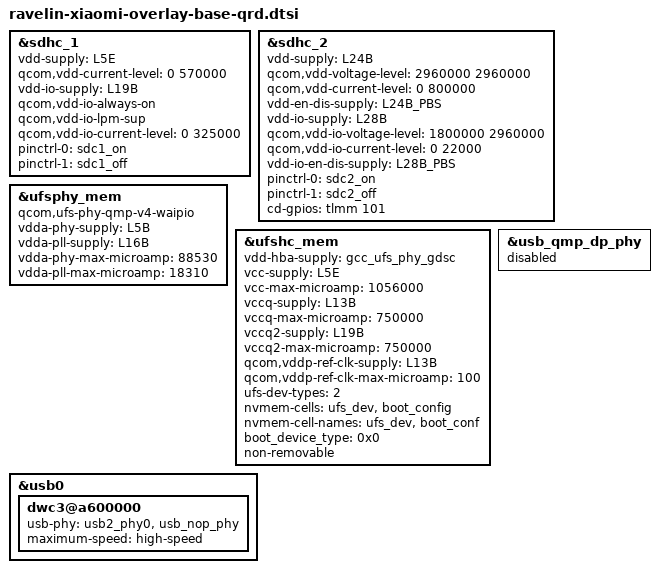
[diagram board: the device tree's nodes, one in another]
// SPDX-License-Identifier: BSD-3-Clause
/*
 * Xiaomi Ravelin board base, ravelin-qrd.dtsi with PM7250B instead of PMI632.
 */

#include "ravelin-pmic-overlay.dtsi"
#include "ravelin-pm7250b.dtsi"
#include "ravelin-thermal-overlay.dtsi"

&sdhc_1 {
	status = "ok";
	vdd-supply = <&L5E>;
	qcom,vdd-current-level = <0 570000>;

	vdd-io-supply = <&L19B>;
	qcom,vdd-io-always-on;
	qcom,vdd-io-lpm-sup;
	qcom,vdd-io-current-level = <0 325000>;

	pinctrl-names = "default", "sleep";
	pinctrl-0 = <&sdc1_on>;
	pinctrl-1 = <&sdc1_off>;
};

&sdhc_2 {
	status = "ok";
	vdd-supply = <&L24B>;
	qcom,vdd-voltage-level = <2960000 2960000>;
	qcom,vdd-current-level = <0 800000>;
	vdd-en-dis-supply = <&L24B_PBS>;

	vdd-io-supply = <&L28B>;
	qcom,vdd-io-voltage-level = <1800000 2960000>;
	qcom,vdd-io-current-level = <0 22000>;
	vdd-io-en-dis-supply = <&L28B_PBS>;

	pinctrl-names = "default", "sleep";
	pinctrl-0 = <&sdc2_on>;
	pinctrl-1 = <&sdc2_off>;

	cd-gpios = <&tlmm 101 GPIO_ACTIVE_HIGH>;
};

&ufsphy_mem {
	compatible = "qcom,ufs-phy-qmp-v4-waipio";

	vdda-phy-supply = <&L5B>;
	vdda-pll-supply = <&L16B>;
	vdda-phy-max-microamp = <88530>;
	vdda-pll-max-microamp = <18310>;

	status = "ok";
};

&ufshc_mem {
	vdd-hba-supply = <&gcc_ufs_phy_gdsc>;

	vcc-supply = <&L5E>;
	vcc-max-microamp = <1056000>;

	vccq-supply = <&L13B>;
	vccq-max-microamp = <750000>;

	vccq2-supply = <&L19B>;
	vccq2-max-microamp = <750000>;

	qcom,vddp-ref-clk-supply = <&L13B>;
	qcom,vddp-ref-clk-max-microamp = <100>;

	ufs-dev-types = <2>;
	nvmem-cells = <&ufs_dev>, <&boot_config>;
	nvmem-cell-names = "ufs_dev", "boot_conf";

	boot_device_type = <0x0>;
	non-removable;

	status = "ok";
};

&usb0 {
	dwc3@a600000 {
		usb-phy = <&usb2_phy0>, <&usb_nop_phy>;
		maximum-speed = "high-speed";
	};
};

&usb_qmp_dp_phy {
	status = "disabled";
};
